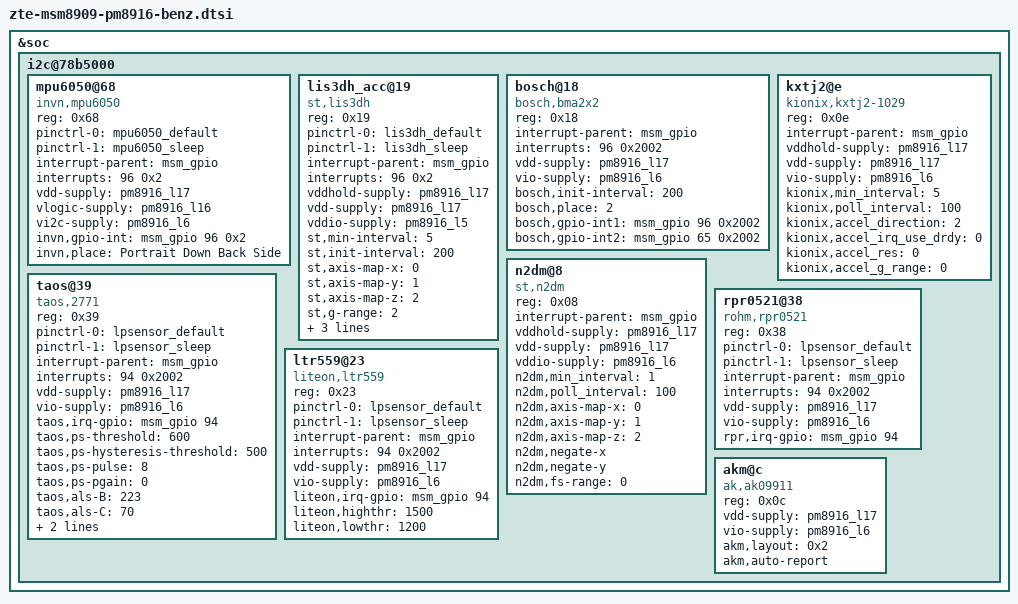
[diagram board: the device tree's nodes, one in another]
/* Copyright (c) 2014, The Linux Foundation. All rights reserved.
*
* This program is free software; you can redistribute it and/or modify
* it under the terms of the GNU General Public License version 2 and
* only version 2 as published by the Free Software Foundation.
*
* This program is distributed in the hope that it will be useful,
* but WITHOUT ANY WARRANTY; without even the implied warranty of
* MERCHANTABILITY or FITNESS FOR A PARTICULAR PURPOSE.  See the
* GNU General Public License for more details.
*/
#include "../touch-key-backlight-benz.dtsi"

&soc {
	i2c@78b5000 { /* BLSP1 QUP1 */
		mpu6050@68 { /* Gyroscope and accelerometer sensor combo */
			compatible = "invn,mpu6050";
			reg = <0x68>;
			pinctrl-names = "mpu_default","mpu_sleep";
			pinctrl-0 = <&mpu6050_default>;
			pinctrl-1 = <&mpu6050_sleep>;
			interrupt-parent = <&msm_gpio>;
			interrupts = <96 0x2>;
			vdd-supply = <&pm8916_l17>;
			vlogic-supply = <&pm8916_l16>;
			vi2c-supply = <&pm8916_l6>;
			invn,gpio-int = <&msm_gpio 96 0x2>;
			invn,place = "Portrait Down Back Side";
		};

		lis3dh_acc@19 {
			compatible = "st,lis3dh";
			reg = <0x19>;
			pinctrl-names = "lis3dh_default","lis3dh_sleep";
			pinctrl-0 = <&lis3dh_default>;
			pinctrl-1 = <&lis3dh_sleep>;
			interrupt-parent = <&msm_gpio>;
			interrupts = <96 0x2>;
			vddhold-supply = <&pm8916_l17>;
			vdd-supply = <&pm8916_l17>;
			vddio-supply = <&pm8916_l5>;
			st,min-interval = <5>;
			st,init-interval = <200>;
			st,axis-map-x = <0>;
			st,axis-map-y = <1>;
			st,axis-map-z = <2>;
			st,g-range =  <2>;
			st,negate-x;
			//st,negate-y;
			st,negate-z;
			//st,enable-int;
			st,gpio-int1 = <&msm_gpio 0xFF 0x2>;
			//st,gpio-int2 = <&msm_gpio 0xFF 0x00>;
		};

		bosch@18 { /* Accelerometer sensor */
			compatible = "bosch,bma2x2";
			reg = <0x18>;
			interrupt-parent = <&msm_gpio>;
			interrupts = <96 0x2002>;
			vdd-supply = <&pm8916_l17>;
			vio-supply = <&pm8916_l6>;
			bosch,init-interval = <200>;
			bosch,place = <2>;
			bosch,gpio-int1 = <&msm_gpio 96 0x2002>;
			bosch,gpio-int2 = <&msm_gpio 65 0x2002>;
		};

/*		kxtj9@e {
			compatible = "kionix,kxtj9";
			reg = <0x0e>;
			interrupt-parent = <&msm_gpio>;
			//interrupts = <96 0x2>;
			vddhold-supply = <&pm8916_l17>;
			vdd-supply = <&pm8916_l17>;
			vio-supply = <&pm8916_l6>;
			kionix,min-interval = <5>;
			kionix,init-interval = <100>;
			kionix,axis-map-x = <1>;
			kionix,axis-map-y = <0>;
			kionix,axis-map-z = <2>;
			kionix,g-range =  <2>;
			//kionix,negate-x;
			kionix,negate-y;
			//kionix,negate-z;
			kionix,res-12bit;
			kionix,gpio-int1 = <&msm_gpio 0xFF 0x02>;
			//kionix,gpio-int2 = <&msm_gpio 0xFF 0x00>;

		};*/

		kxtj2@e {
			compatible = "kionix,kxtj2-1029";
			reg = <0x0e>;
			interrupt-parent = <&msm_gpio>;
			//interrupts = <96 0x2>;
			vddhold-supply = <&pm8916_l17>;
			vdd-supply = <&pm8916_l17>;
			vio-supply = <&pm8916_l6>;
			kionix,min_interval = <5>;
			kionix,poll_interval = <100>;
			kionix,accel_direction = <2>;
			kionix,accel_irq_use_drdy = <0>;
			//0 is 12BIT, 1 is 8BIT, 2 is 6BIT
			kionix,accel_res = <0>;
			//0 is 2g, 1 is 4g, 2 is 6g, 3 is 8g
			kionix,accel_g_range =  <0>;
		};

		n2dm@8 {
			compatible = "st,n2dm";
			reg = <0x08>;
			interrupt-parent = <&msm_gpio>;
			//interrupts = <96 0x2>;
			vddhold-supply = <&pm8916_l17>;
			vdd-supply = <&pm8916_l17>;
			vddio-supply = <&pm8916_l6>;
			n2dm,min_interval = <1>;
			n2dm,poll_interval = <100>;
			n2dm,axis-map-x = <0>;
			n2dm,axis-map-y = <1>;
			n2dm,axis-map-z = <2>;
			n2dm,negate-x;
			n2dm,negate-y;
			//n2dm,negate-z;
			//0 is 2g, 16 is 4g, 32 is 8g, 48 is 16g
			n2dm,fs-range =  <0>;
		};


	/*	avago@39 {
			compatible = "avago,apds9900";
			reg = <0x39>;
			pinctrl-names = "default","sleep";
			pinctrl-0 = <&apds99xx_default>;
			pinctrl-1 = <&apds99xx_sleep>;
			interrupt-parent = <&msm_gpio>;
			interrupts = <113 0x2002>;
			vdd-supply = <&pm8916_l17>;
			vio-supply = <&pm8916_l6>;
			avago,irq-gpio = <&msm_gpio 113 0x2002>;
			avago,ps-threshold = <600>;
			avago,ps-hysteresis-threshold = <500>;
			avago,ps-pulse = <8>;
			avago,ps-pgain = <0>;
			avago,als-B = <223>;
			avago,als-C = <70>;
			avago,als-D = <142>;
			avago,ga-value = <48>;
		}; */

		taos@39 {
			compatible = "taos,2771";
			reg = <0x39>;
			pinctrl-names = "lpsensor_default","lpsensor_sleep";
			pinctrl-0 = <&lpsensor_default>;
			pinctrl-1 = <&lpsensor_sleep>;
			interrupt-parent = <&msm_gpio>;
			interrupts = <94 0x2002>;
			vdd-supply = <&pm8916_l17>;
			vio-supply = <&pm8916_l6>;
			taos,irq-gpio = <&msm_gpio 94 0x2002>;
			taos,ps-threshold = <600>;
			taos,ps-hysteresis-threshold = <500>;
			taos,ps-pulse = <8>;
			taos,ps-pgain = <0>;
			taos,als-B = <223>;
			taos,als-C = <70>;
			taos,als-D = <142>;
			taos,ga-value = <48>;
		};

		rpr0521@38 {
			compatible = "rohm,rpr0521";
			reg = <0x38>;
			pinctrl-names = "lpsensor_default","lpsensor_sleep";
			pinctrl-0 = <&lpsensor_default>;
			pinctrl-1 = <&lpsensor_sleep>;
			interrupt-parent = <&msm_gpio>;
			interrupts = <94 0x2002>;
			vdd-supply = <&pm8916_l17>;
			vio-supply = <&pm8916_l6>;
			rpr,irq-gpio = <&msm_gpio 94 0x2002>;
		};

		ltr559@23 {
			compatible = "liteon,ltr559";
			reg = <0x23>;
			pinctrl-names = "lpsensor_default","lpsensor_sleep";
			pinctrl-0 = <&lpsensor_default>;
			pinctrl-1 = <&lpsensor_sleep>;
			interrupt-parent = <&msm_gpio>;
			interrupts = <94 0x2002>;
			vdd-supply = <&pm8916_l17>;
			vio-supply = <&pm8916_l6>;
			liteon,irq-gpio = <&msm_gpio 94 0x2002>;
			liteon,highthr = <1500>;
			liteon,lowthr = <1200>;
		};

		//akm@c {
		//	compatible = "ak,ak8963";
		//	reg = <0x0c>;
		//	pinctrl-names = "ak8963_default", "ak8963_sleep";
		//	pinctrl-0 = <&ak8963_default>;
		//	pinctrl-1 = <&ak8963_sleep>;
		//	interrupt-parent = <&msm_gpio>;
		//	interrupts = <69 0x2>;
		//	vdd-supply = <&pm8916_l17>;
		//	vio-supply = <&pm8916_l6>;
		//	ak,layout = <0x6>;
		//	ak,auto-report;
		//};

		akm@c {
			compatible = "ak,ak09911";
			reg = <0x0c>;
			vdd-supply = <&pm8916_l17>;
			vio-supply = <&pm8916_l6>;
			akm,layout = <0x2>;
			akm,auto-report;
		};

	};
};
